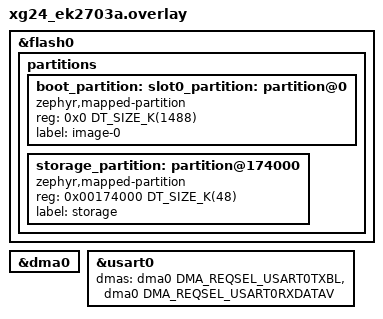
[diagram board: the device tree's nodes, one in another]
/*
 *	Copyright (c) 2026 Project CHIP Authors
 *	All rights reserved.
 *
 *	Licensed under the Apache License, Version 2.0 (the "License");
 *	you may not use this file except in compliance with the License.
 *	You may obtain a copy of the License at
 *
 *	    http://www.apache.org/licenses/LICENSE-2.0
 *
 *	Unless required by applicable law or agreed to in writing, software
 *	distributed under the License is distributed on an "AS IS" BASIS
 *	WITHOUT WARRANTIES OR CONDITIONS OF ANY KIND, either express or implied.
 *	See the License for the specific language governing permissions and
 *	limitations under the License.
 */

/*
 * Internal flash (1536 KiB): application (1488 KiB) + storage (48 KiB).
 * MCUboot and OTA are deliberately disabled for this board.
 */

/delete-node/ &slot0_partition;
/delete-node/ &slot1_partition;
/delete-node/ &storage_partition;

&flash0 {
	partitions {
		boot_partition: slot0_partition: partition@0 {
			compatible = "zephyr,mapped-partition";
			reg = <0x0 DT_SIZE_K(1488)>;
			label = "image-0";
		};

		storage_partition: partition@174000 {
			compatible = "zephyr,mapped-partition";
			reg = <0x00174000 DT_SIZE_K(48)>;
			label = "storage";
		};
	};
};

&dma0 {
	status = "okay";
};

&usart0 {
	dmas = <&dma0 DMA_REQSEL_USART0TXBL>,
		   <&dma0 DMA_REQSEL_USART0RXDATAV>;
	dma-names = "tx", "rx";
};
